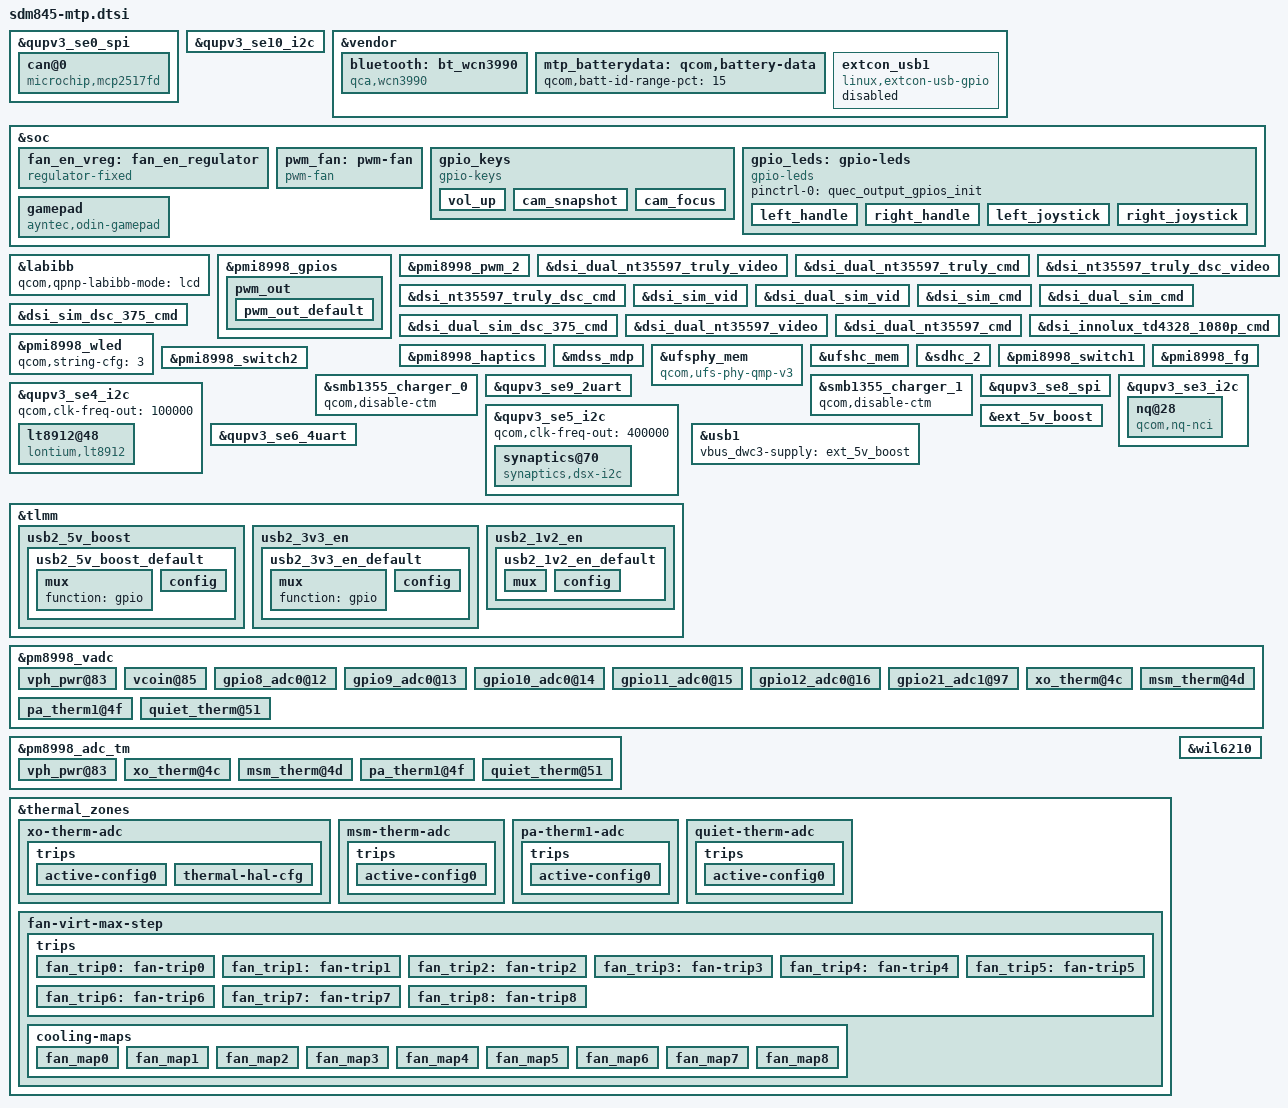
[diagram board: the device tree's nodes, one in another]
// SPDX-License-Identifier: GPL-2.0-only
/*
 * Copyright (c) 2016-2019, The Linux Foundation. All rights reserved.
 */

#include <dt-bindings/iio/qcom,spmi-vadc.h>
#include <dt-bindings/gpio/gpio.h>
#include "sdm845-pmic-overlay.dtsi"
#include "sdm845-pinctrl-overlay.dtsi"
#include "sdm845-camera-sensor-mtp.dtsi"

&qupv3_se0_spi {
	status = "ok";
	can@0 {
		compatible = "microchip,mcp2517fd";
		reg = <0>;
		clocks = <&clk40M>;
		interrupt-parent = <&tlmm>;
		interrupts = <34 0>;
		interrupt-names = "can_irq";
		spi-max-frequency = <10000000>;
		gpio-controller;
		status = "okay";
	};
};

&qupv3_se10_i2c {
#include "smb1355.dtsi"
};

&vendor {
	bluetooth: bt_wcn3990 {
		compatible = "qca,wcn3990";
		qca,bt-vdd-io-supply = <&pm8998_s3>;
		qca,bt-vdd-xtal-supply = <&pm8998_s5>;
		qca,bt-vdd-core-supply = <&pm8998_l7>;
		qca,bt-vdd-pa-supply = <&pm8998_l17>;
		qca,bt-vdd-ldo-supply = <&pm8998_l25>;

		qca,bt-vdd-io-voltage-level = <1352000 1352000>;
		qca,bt-vdd-xtal-voltage-level = <2040000 2040000>;
		qca,bt-vdd-core-voltage-level = <1800000 1800000>;
		qca,bt-vdd-pa-voltage-level = <1304000 1304000>;
		qca,bt-vdd-ldo-voltage-level = <3312000 3312000>;

		qca,bt-vdd-io-current-level = <1>; /* LPM/PFM */
		qca,bt-vdd-xtal-current-level = <1>; /* LPM/PFM */
		qca,bt-vdd-core-current-level = <1>; /* LPM/PFM */
		qca,bt-vdd-pa-current-level = <1>; /* LPM/PFM */
		qca,bt-vdd-ldo-current-level = <1>; /* LPM/PFM */
	};
};

&soc {
	fan_en_vreg: fan_en_regulator {
		compatible = "regulator-fixed";
		regulator-name = "fan_en";
		gpio = <&tlmm 44 0>;
		enable-active-high;
		regulator-boot-off;
	};

	pwm_fan: pwm-fan {
		compatible = "pwm-fan";
		pwms = <&pmi8998_pwm_2 0 50000>;
		fan-supply = <&fan_en_vreg>;
		#cooling-cells = <2>;
		cooling-levels = <0 51 77 102 128 153 179 204 230 255>;
		pinctrl-names = "default";
		pinctrl-0 = <&pwm_out_default>;
	};

	gpio_keys {
		compatible = "gpio-keys";
		label = "gpio-keys";

		pinctrl-names = "default";
		pinctrl-0 = <&key_vol_up_default
			     &key_cam_snapshot_default>;

		vol_up {
			label = "volume_up";
			gpios = <&pm8998_gpios 6 GPIO_ACTIVE_LOW>;
			linux,input-type = <1>;
			linux,code = <115>;
			gpio-key,wakeup;
			debounce-interval = <15>;
			linux,can-disable;
		};

		cam_snapshot {
			label = "cam_snapshot";
			gpios = <&pm8998_gpios 7 GPIO_ACTIVE_LOW>;
			linux,input-type = <1>;
			linux,code = <766>;
			gpio-key,wakeup;
			debounce-interval = <15>;
			linux,can-disable;
		};

		cam_focus {
			label = "cam_focus";
			gpios = <&pm8998_gpios 8 GPIO_ACTIVE_LOW>;
			linux,input-type = <1>;
			linux,code = <528>;
			gpio-key,wakeup;
			debounce-interval = <15>;
			linux,can-disable;
		};
	};

	gpio_leds: gpio-leds {
		compatible = "gpio-leds";
		pinctrl-names = "default";
		pinctrl-0 = <&quec_output_gpios_init>;

		left_handle {
			label = "left:strip";
			gpios = <&tlmm 129 GPIO_ACTIVE_HIGH>;
			default-state = "off";
		};

		right_handle {
			label = "right:strip";
			gpios = <&tlmm 87 GPIO_ACTIVE_HIGH>;
			default-state = "off";
		};

		left_joystick {
			label = "left:stick";
			gpios = <&tlmm 25 GPIO_ACTIVE_HIGH>;
			default-state = "off";
		};

		right_joystick {
			label = "right:stick";
			gpios = <&tlmm 7 GPIO_ACTIVE_HIGH>;
			default-state = "off";
		};
	};

	gamepad: gamepad {
		compatible = "ayntec,odin-gamepad";
		status = "okay";

		ayn,default-layout = "xbox";

		pinctrl-names = "default";
		pinctrl-0 = <&quec_input_gpios_init>;

		dpad-up-gpios     = <&tlmm 124 GPIO_ACTIVE_LOW>;
		dpad-down-gpios   = <&tlmm 128 GPIO_ACTIVE_LOW>;
		dpad-left-gpios   = <&tlmm  52 GPIO_ACTIVE_LOW>;
		dpad-right-gpios  = <&tlmm 122 GPIO_ACTIVE_LOW>;

		west-btn-gpios    = <&tlmm  41 GPIO_ACTIVE_LOW>;
		north-btn-gpios   = <&tlmm  92 GPIO_ACTIVE_LOW>;
		south-btn-gpios   = <&tlmm  95 GPIO_ACTIVE_LOW>;
		east-btn-gpios    = <&tlmm  96 GPIO_ACTIVE_LOW>;

		l1-btn-gpios      = <&tlmm  26 GPIO_ACTIVE_LOW>;
		r1-btn-gpios      = <&tlmm  91 GPIO_ACTIVE_LOW>;

		select-btn-gpios  = <&tlmm   0 GPIO_ACTIVE_LOW>;
		start-btn-gpios   = <&tlmm   3 GPIO_ACTIVE_LOW>;
		thumb-l-btn-gpios = <&tlmm  40 GPIO_ACTIVE_LOW>;
		thumb-r-btn-gpios = <&tlmm  22 GPIO_ACTIVE_LOW>;
		home-btn-gpios    = <&tlmm  49 GPIO_ACTIVE_LOW>;

		rear-l-btn-gpios  = <&tlmm 116 GPIO_ACTIVE_LOW>;
		rear-r-btn-gpios  = <&tlmm  24 GPIO_ACTIVE_LOW>;

		io-channels = <&pm8998_vadc ADC_GPIO2>,
		      <&pm8998_vadc ADC_GPIO3>,
		      <&pm8998_vadc ADC_GPIO6_DIV3>,
		      <&pm8998_vadc ADC_GPIO5>,
		      <&pm8998_vadc ADC_GPIO1>,
		      <&pm8998_vadc ADC_GPIO4>;
		io-channel-names = "gpio9_adc0", "gpio10_adc0", "gpio21_adc1",
			   "gpio12_adc0", "gpio8_adc0", "gpio11_adc0";
		#io-channel-cells = <1>;
	};
};

&labibb {
	status = "ok";
	qcom,qpnp-labibb-mode = "lcd";
};

&pmi8998_gpios {
	pwm_out {
		pwm_out_default: pwm_out_default {
			pins = "gpio5";
			function = "func1";
			bias-disable;
			power-source = <0>;
			output-low;
			qcom,drive-strength = <3>;
			drive-push-pull;
		};
	};
};

&pmi8998_pwm_2 {
    status = "okay";
};

&dsi_dual_nt35597_truly_video {
	qcom,panel-supply-entries = <&dsi_panel_pwr_supply>;
	qcom,mdss-dsi-bl-pmic-control-type = "bl_ctrl_wled";
	qcom,mdss-dsi-bl-min-level = <1>;
	qcom,mdss-dsi-bl-max-level = <4095>;
	qcom,mdss-dsi-mode-sel-gpio-state = "dual_port";
	qcom,panel-mode-gpio = <&tlmm 52 0>;
	qcom,platform-reset-gpio = <&tlmm 6 0>;
};

&dsi_dual_nt35597_truly_cmd {
	qcom,panel-supply-entries = <&dsi_panel_pwr_supply>;
	qcom,mdss-dsi-bl-pmic-control-type = "bl_ctrl_wled";
	qcom,mdss-dsi-bl-min-level = <1>;
	qcom,mdss-dsi-bl-max-level = <4095>;
	qcom,mdss-dsi-mode-sel-gpio-state = "dual_port";
	qcom,panel-mode-gpio = <&tlmm 52 0>;
	qcom,platform-reset-gpio = <&tlmm 6 0>;
	qcom,platform-te-gpio = <&tlmm 10 0>;
};

&dsi_nt35597_truly_dsc_video {
	qcom,panel-supply-entries = <&dsi_panel_pwr_supply>;
	qcom,mdss-dsi-bl-pmic-control-type = "bl_ctrl_wled";
	qcom,mdss-dsi-bl-min-level = <1>;
	qcom,mdss-dsi-bl-max-level = <4095>;
	qcom,mdss-dsi-mode-sel-gpio-state = "single_port";
	qcom,panel-mode-gpio = <&tlmm 52 0>;
	qcom,platform-reset-gpio = <&tlmm 6 0>;
};

&dsi_nt35597_truly_dsc_cmd {
	qcom,panel-supply-entries = <&dsi_panel_pwr_supply>;
	qcom,mdss-dsi-bl-pmic-control-type = "bl_ctrl_wled";
	qcom,mdss-dsi-bl-min-level = <1>;
	qcom,mdss-dsi-bl-max-level = <4095>;
	qcom,mdss-dsi-mode-sel-gpio-state = "single_port";
	qcom,panel-mode-gpio = <&tlmm 52 0>;
	qcom,platform-reset-gpio = <&tlmm 6 0>;
	qcom,platform-te-gpio = <&tlmm 10 0>;
};

&dsi_sim_vid {
	qcom,panel-supply-entries = <&dsi_panel_pwr_supply>;
	qcom,mdss-dsi-bl-pmic-control-type = "bl_ctrl_wled";
	qcom,platform-reset-gpio = <&tlmm 6 0>;
};

&dsi_dual_sim_vid {
	qcom,panel-supply-entries = <&dsi_panel_pwr_supply>;
	qcom,mdss-dsi-bl-pmic-control-type = "bl_ctrl_wled";
	qcom,platform-reset-gpio = <&tlmm 6 0>;
};

&dsi_sim_cmd {
	qcom,panel-supply-entries = <&dsi_panel_pwr_supply>;
	qcom,mdss-dsi-bl-pmic-control-type = "bl_ctrl_wled";
	qcom,platform-reset-gpio = <&tlmm 6 0>;
};

&dsi_dual_sim_cmd {
	qcom,panel-supply-entries = <&dsi_panel_pwr_supply>;
	qcom,mdss-dsi-bl-pmic-control-type = "bl_ctrl_wled";
	qcom,platform-reset-gpio = <&tlmm 6 0>;
};

&dsi_sim_dsc_375_cmd {
	qcom,panel-supply-entries = <&dsi_panel_pwr_supply>;
	qcom,mdss-dsi-bl-pmic-control-type = "bl_ctrl_wled";
	qcom,platform-reset-gpio = <&tlmm 6 0>;
};

&dsi_dual_sim_dsc_375_cmd {
	qcom,panel-supply-entries = <&dsi_panel_pwr_supply>;
	qcom,mdss-dsi-bl-pmic-control-type = "bl_ctrl_wled";
	qcom,platform-reset-gpio = <&tlmm 6 0>;
};

&dsi_dual_nt35597_video {
	qcom,panel-supply-entries = <&dsi_panel_pwr_supply>;
	qcom,mdss-dsi-bl-pmic-control-type = "bl_ctrl_wled";
	qcom,mdss-dsi-bl-min-level = <1>;
	qcom,mdss-dsi-bl-max-level = <4095>;
	qcom,mdss-dsi-mode-sel-gpio-state = "dual_port";
	qcom,panel-mode-gpio = <&tlmm 52 0>;
	qcom,platform-reset-gpio = <&tlmm 6 0>;
};

&dsi_dual_nt35597_cmd {
	qcom,panel-supply-entries = <&dsi_panel_pwr_supply>;
	qcom,mdss-dsi-bl-pmic-control-type = "bl_ctrl_wled";
	qcom,mdss-dsi-bl-min-level = <1>;
	qcom,mdss-dsi-bl-max-level = <4095>;
	qcom,mdss-dsi-mode-sel-gpio-state = "dual_port";
	qcom,panel-mode-gpio = <&tlmm 52 0>;
	qcom,platform-reset-gpio = <&tlmm 6 0>;
	qcom,platform-te-gpio = <&tlmm 10 0>;
};

&dsi_innolux_td4328_1080p_cmd {
	qcom,panel-supply-entries = <&dsi_panel_pwr_supply>;
	qcom,mdss-dsi-bl-pmic-control-type = "bl_ctrl_wled";
	qcom,mdss-dsi-bl-min-level = <1>;
	qcom,mdss-dsi-bl-max-level = <4095>;
	qcom,mdss-dsi-mode-sel-gpio-state = "single_port";
	qcom,5v-boost-gpio = <&tlmm 120 0>;
	qcom,platform-mipi-mode-oe = <&tlmm 50 0>;
	qcom,platform-reset-gpio = <&tlmm 6 0>;
	qcom,platform-te-gpio = <&tlmm 10 0>;
};

&pmi8998_wled {
	qcom,string-cfg = <3>; /* [00 01] */
	status = "okay";
};

&pmi8998_haptics {
	qcom,vmax-mv = <3596>;
	qcom,actuator-type = <1>;
	status = "okay";
};

&mdss_mdp {
	#cooling-cells = <2>;
};

&ufsphy_mem {
	compatible = "qcom,ufs-phy-qmp-v3";

	vdda-phy-supply = <&pm8998_l1>; /* 0.88v */
	vdda-pll-supply = <&pm8998_l26>; /* 1.2v */
	vdda-phy-max-microamp = <62900>;
	vdda-pll-max-microamp = <18300>;

	status = "ok";
};

&ufshc_mem {
	vdd-hba-supply = <&ufs_phy_gdsc>;
	vdd-hba-fixed-regulator;
	vcc-supply = <&pm8998_l20>;
	vcc-voltage-level = <2950000 2960000>;
	vccq2-supply = <&pm8998_s4>;
	vcc-max-microamp = <600000>;
	vccq2-max-microamp = <600000>;

	qcom,vddp-ref-clk-supply = <&pm8998_l2>;
	qcom,vddp-ref-clk-max-microamp = <100>;

	status = "ok";
};

&sdhc_2 {
	vdd-supply = <&pm8998_l21>;
	qcom,vdd-voltage-level = <2950000 2960000>;
	qcom,vdd-current-level = <200 800000>;

	vdd-io-supply = <&pm8998_l13>;
	qcom,vdd-io-voltage-level = <1808000 2960000>;
	qcom,vdd-io-current-level = <200 22000>;

	pinctrl-names = "active", "sleep", "ds_400KHz",
			"ds_50MHz", "ds_100MHz", "ds_200MHz";
	pinctrl-0 = <&sdc2_clk_on  &sdc2_cmd_on &sdc2_data_on &storage_cd>;
	pinctrl-1 = <&sdc2_clk_off &sdc2_cmd_off &sdc2_data_off &storage_cd>;
	pinctrl-2 = <&sdc2_clk_ds_400KHz
			&sdc2_cmd_ds_400KHz &sdc2_data_ds_400KHz>;
	pinctrl-3 = <&sdc2_clk_ds_50MHz
			&sdc2_cmd_ds_50MHz &sdc2_data_ds_50MHz>;
	pinctrl-4 = <&sdc2_clk_ds_100MHz
			&sdc2_cmd_ds_100MHz &sdc2_data_ds_100MHz>;
	pinctrl-5 = <&sdc2_clk_ds_200MHz
			&sdc2_cmd_ds_200MHz &sdc2_data_ds_200MHz>;

	cd-gpios = <&tlmm 126 GPIO_ACTIVE_LOW>;

	status = "ok";
};

&pmi8998_switch1 {
	pinctrl-names = "led_enable", "led_disable";
	pinctrl-0 = <&flash_led3_front_en>;
	pinctrl-1 = <&flash_led3_front_dis>;
};

&pmi8998_switch2 {
	pinctrl-names = "led_enable", "led_disable";
	pinctrl-0 = <&flash_led3_iris_en>;
	pinctrl-1 = <&flash_led3_iris_dis>;
};

&vendor {
	mtp_batterydata: qcom,battery-data {
		qcom,batt-id-range-pct = <15>;
		// #include "./battery/fg-gen3-batterydata-itech-3000mah.dtsi"
		// #include "./battery/fg-gen3-batterydata-ascent-3450mah.dtsi"
		// #include "./battery/fg-gen3-batterydata-demo-6000mah.dtsi"
		#include "./ayn/fg-gen3-batterydata-chijin-6600mah.dtsi"
	};

	extcon_usb1: extcon_usb1 {
		compatible = "linux,extcon-usb-gpio";
		vbus-gpio = <&pmi8998_gpios 8 GPIO_ACTIVE_HIGH>;

		pinctrl-names = "default";
		pinctrl-0 = <&usb2_vbus_det_default>;
		status = "disabled";
	};
};

&pmi8998_fg {
	qcom,battery-data = <&mtp_batterydata>;
	qcom,fg-force-load-profile;
};

&smb1355_charger_0 {
	status = "ok";
	qcom,disable-ctm;
};

&smb1355_charger_1 {
	status = "ok";
	qcom,disable-ctm;
};

&qupv3_se9_2uart {
	status = "ok";
};

&qupv3_se8_spi {
	status = "ok";
};

&qupv3_se3_i2c {
	status = "ok";
	nq@28 {
		compatible = "qcom,nq-nci";
		reg = <0x28>;
		qcom,nq-irq = <&tlmm 63 0x00>;
		qcom,nq-ven = <&tlmm 12 0x00>;
		qcom,nq-firm = <&tlmm 62 0x00>;
		qcom,nq-clkreq = <&pm8998_gpios 21 0x00>;
		qcom,nq-esepwr = <&tlmm 116 0x00>;
		interrupt-parent = <&tlmm>;
		interrupts = <63 IRQ_TYPE_LEVEL_HIGH>;
		interrupt-names = "nfc_irq";
		pinctrl-names = "nfc_active", "nfc_suspend";
		pinctrl-0 = <&nfc_int_active
			     &nfc_enable_active
			     &nfc_clk_default>;
		pinctrl-1 = <&nfc_int_suspend &nfc_enable_suspend>;
	};
};

&qupv3_se4_i2c {
	status = "ok";
	qcom,clk-freq-out = <100000>;
	lt8912@48 {
		compatible = "lontium,lt8912";
		status = "okay";
		reg = <0x48>;
		qcom,ext-disp = <&ext_disp>;
		lt,enable-audio = <1>;
		lt,pwren-gpio = <&tlmm 8 0x00>;
		lt,reset-gpio = <&tlmm 12 0x00>;
		lt,hdmien-gpio = <&tlmm 13 0x00>;
		lt,hdmidet-gpio = <&tlmm 121 0x00>;
		pinctrl-names = "hdmidet_active","hdmidet_suspend";
		pinctrl-0 = <&hdmi_det_active>;
		pinctrl-1 = <&hdmi_det_suspend>;
		//lt,hpd-gpio = <&tlmm 9 0x00>;
		//interrupt-parent = <&tlmm>;
		//interrupts = <9 0>;
		//interrupt-names = "hdmi_hpd_irq1";
	};
};

&qupv3_se5_i2c {
	status = "ok";
	qcom,clk-freq-out = <400000>;
	synaptics@70 {
		compatible = "synaptics,dsx-i2c";
		reg = <0x70>;
		interrupt-parent = <&tlmm>;
		interrupts = <125 0x2>;
		pinctrl-names = "pmx_ts_active", "pmx_ts_suspend";
		pinctrl-0 = <&ts_int_active &ts_reset_active>;
		pinctrl-1 = <&ts_int_suspend &ts_reset_suspend>;
		vdd_ana-supply = <&pm8998_l28>;
		vcc_i2c-supply  = <&pm8998_l14>;
		synaptics,pwr-reg-name = "vdd_ana";
		synaptics,bus-reg-name = "vcc_i2c";
		synaptics,ub-i2c-addr = <0x20>;
		/* IRQF_ONESHOT | IRQF_TRIGGER_LOW */
		synaptics,irq-gpio = <&tlmm 125 0x2008>;
		synaptics,irq-on-state = <0>;
		synaptics,reset-gpio = <&tlmm 104 0>;	//hrb
		synaptics,power-delay-ms = <200>;
		synaptics,reset-delay-ms = <200>;
		synaptics,reset-on-state = <0>;
		synaptics,reset-active-ms = <20>;
	};
};

&qupv3_se10_i2c {
	status = "ok";
};

&qupv3_se6_4uart {
	status = "ok";
};

&tlmm {
	usb2_5v_boost {
		usb2_5v_boost_default: usb2_5v_boost_default  {
			mux {
				//pins = "gpio129";
				function = "gpio";
			};

			config {
				//pins = "gpio129";
				drive-strength = <2>;
				output-low;
			};
		};
	};

	usb2_3v3_en {
		usb2_3v3_en_default: usb2_3v3_en_default  {
			mux {
				//pins = "gpio128";
				function = "gpio";
			};

			config {
				//pins = "gpio128";
				drive-strength = <2>;
				output-high;
			};
		};
	};

	usb2_1v2_en {
		usb2_1v2_en_default: usb2_1v2_en_default  {
			mux {
				pins = "gpio135";
				function = "gpio";
			};

			config {
				pins = "gpio135";
				drive-strength = <2>;
				output-high;
			};
		};
	};
};

&ext_5v_boost {
	status = "ok";
	pinctrl-names = "default";
	pinctrl-0 = <&usb2_5v_boost_default
				&usb2_3v3_en_default
				&usb2_1v2_en_default>;
};

&usb1 {
	status = "ok";
	vbus_dwc3-supply = <&ext_5v_boost>;
};

&pm8998_vadc {
	vph_pwr@83 {
		label = "vph_pwr";
		reg = <ADC_VPH_PWR>;
		qcom,pre-scaling = <1 1>;
	};

	vcoin@85 {
		label = "vcoin";
		reg = <ADC_VCOIN>;
		qcom,pre-scaling = <1 1>;
	};

	gpio8_adc0@12 {
		label = "gpio8_adc0";
		reg = <ADC_GPIO1>;
		qcom,pre-scaling = <1 1>;
	};

	gpio9_adc0@13 {
		label = "gpio9_adc0";
		reg = <ADC_GPIO2>;
		qcom,pre-scaling = <1 1>;
	};

	gpio10_adc0@14 {
		label = "gpio10_adc0";
		reg = <ADC_GPIO3>;
		qcom,pre-scaling = <1 1>;
	};

	gpio11_adc0@15 {
		label = "gpio11_adc0";
		reg = <ADC_GPIO4>;
		qcom,pre-scaling = <1 1>;
	};

	gpio12_adc0@16 {
		label = "gpio12_adc0";
		reg = <ADC_GPIO5>;
		qcom,pre-scaling = <1 1>;
	};

	gpio21_adc1@97 {
		label = "gpio21_adc1";
		reg = <ADC_GPIO6_DIV3>;
		qcom,pre-scaling = <1 3>;
	};

	xo_therm@4c {
		label = "xo_therm";
		reg = <ADC_XO_THERM_PU2>;
		qcom,ratiometric;
		qcom,hw-settle-time = <200>;
		qcom,pre-scaling = <1 1>;
	};

	msm_therm@4d {
		label = "msm_therm";
		reg = <ADC_AMUX_THM1_PU2>;
		qcom,ratiometric;
		qcom,hw-settle-time = <200>;
		qcom,pre-scaling = <1 1>;
	};

	pa_therm1@4f {
		label = "pa_therm1";
		reg = <ADC_AMUX_THM3_PU2>;
		qcom,ratiometric;
		qcom,hw-settle-time = <200>;
		qcom,pre-scaling = <1 1>;
	};

	quiet_therm@51 {
		label = "quiet_therm";
		reg = <ADC_AMUX_THM5_PU2>;
		qcom,ratiometric;
		qcom,hw-settle-time = <200>;
		qcom,pre-scaling = <1 1>;
	};
};

&pm8998_adc_tm {
	io-channels = <&pm8998_vadc ADC_VPH_PWR>,
			<&pm8998_vadc ADC_XO_THERM_PU2>,
			<&pm8998_vadc ADC_AMUX_THM1_PU2>,
			<&pm8998_vadc ADC_AMUX_THM3_PU2>,
			<&pm8998_vadc ADC_AMUX_THM5_PU2>;

	/* Channel nodes */
	vph_pwr@83 {
		label = "vph_pwr";
		reg = <ADC_VPH_PWR>;
	};

	xo_therm@4c {
		label = "xo_therm";
		reg = <ADC_XO_THERM_PU2>;
		qcom,ratiometric;
		qcom,hw-settle-time = <200>;
	};

	msm_therm@4d {
		label = "msm_therm";
		reg = <ADC_AMUX_THM1_PU2>;
		qcom,ratiometric;
		qcom,hw-settle-time = <200>;
	};

	pa_therm1@4f {
		label = "pa_therm1";
		reg = <ADC_AMUX_THM3_PU2>;
		qcom,ratiometric;
		qcom,hw-settle-time = <200>;
	};

	quiet_therm@51 {
		label = "quiet_therm";
		reg = <ADC_AMUX_THM5_PU2>;
		qcom,ratiometric;
		qcom,hw-settle-time = <200>;
	};
};

&thermal_zones {
	xo-therm-adc {
		polling-delay-passive = <0>;
		polling-delay = <0>;
		thermal-sensors = <&pm8998_adc_tm ADC_XO_THERM_PU2>;
		wake-capable-sensor;
		thermal-governor = "user_space";

		trips {
			active-config0 {
				temperature = <125000>;
				hysteresis = <10000>;
				type = "passive";
			};

			thermal-hal-cfg {
				temperature = <115000>;
				hysteresis = <5000>;
				type = "passive";
			};
		};
	};

	msm-therm-adc {
		polling-delay-passive = <0>;
		polling-delay = <0>;
		thermal-sensors = <&pm8998_adc_tm ADC_AMUX_THM1_PU2>;
		wake-capable-sensor;
		thermal-governor = "user_space";

		trips {
			active-config0 {
				temperature = <125000>;
				hysteresis = <10000>;
				type = "passive";
			};
		};
	};

	pa-therm1-adc {
		polling-delay-passive = <0>;
		polling-delay = <0>;
		thermal-sensors = <&pm8998_adc_tm ADC_AMUX_THM3_PU2>;
		wake-capable-sensor;
		thermal-governor = "user_space";

		trips {
			active-config0 {
				temperature = <125000>;
				hysteresis = <10000>;
				type = "passive";
			};
		};
	};

	quiet-therm-adc {
		polling-delay-passive = <0>;
		polling-delay = <0>;
		thermal-sensors = <&pm8998_adc_tm ADC_AMUX_THM5_PU2>;
		wake-capable-sensor;
		thermal-governor = "user_space";

		trips {
			active-config0 {
				temperature = <125000>;
				hysteresis = <10000>;
				type = "passive";
			};
		};
	};

	fan-virt-max-step {
		polling-delay-passive = <100>;
		polling-delay = <1000>;
		thermal-governor = "step_wise";
		wake-capable-sensor;
		trips {
			fan_trip0: fan-trip0 {
				temperature = <55000>;
				hysteresis = <5000>;
				type = "active";
			};
			fan_trip1: fan-trip1 {
				temperature = <59000>;
				hysteresis = <5000>;
				type = "active";
			};
			fan_trip2: fan-trip2 {
				temperature = <63000>;
				hysteresis = <5000>;
				type = "active";
			};
			fan_trip3: fan-trip3 {
				temperature = <67000>;
				hysteresis = <5000>;
				type = "active";
			};
			fan_trip4: fan-trip4 {
				temperature = <71000>;
				hysteresis = <5000>;
				type = "active";
			};
			fan_trip5: fan-trip5 {
				temperature = <75000>;
				hysteresis = <5000>;
				type = "active";
			};
			fan_trip6: fan-trip6 {
				temperature = <79000>;
				hysteresis = <5000>;
				type = "active";
			};
			fan_trip7: fan-trip7 {
				temperature = <83000>;
				hysteresis = <5000>;
				type = "active";
			};
			fan_trip8: fan-trip8 {
				temperature = <87000>;
				hysteresis = <5000>;
				type = "active";
			};
		};
		cooling-maps {
			fan_map0 {
				trip = <&fan_trip0>;
				cooling-device = <&pwm_fan 1 1>;
			};
			fan_map1 {
				trip = <&fan_trip1>;
				cooling-device = <&pwm_fan 2 2>;
			};
			fan_map2 {
				trip = <&fan_trip2>;
				cooling-device = <&pwm_fan 3 3>;
			};
			fan_map3 {
				trip = <&fan_trip3>;
				cooling-device = <&pwm_fan 4 4>;
			};
			fan_map4 {
				trip = <&fan_trip4>;
				cooling-device = <&pwm_fan 5 5>;
			};
			fan_map5 {
				trip = <&fan_trip5>;
				cooling-device = <&pwm_fan 6 6>;
			};
			fan_map6 {
				trip = <&fan_trip6>;
				cooling-device = <&pwm_fan 7 7>;
			};
			fan_map7 {
				trip = <&fan_trip7>;
				cooling-device = <&pwm_fan 8 8>;
			};
			fan_map8 {
				trip = <&fan_trip8>;
				cooling-device = <&pwm_fan 9 9>;
			};
		};
	};
};

&wil6210 {
	status = "ok";
};
